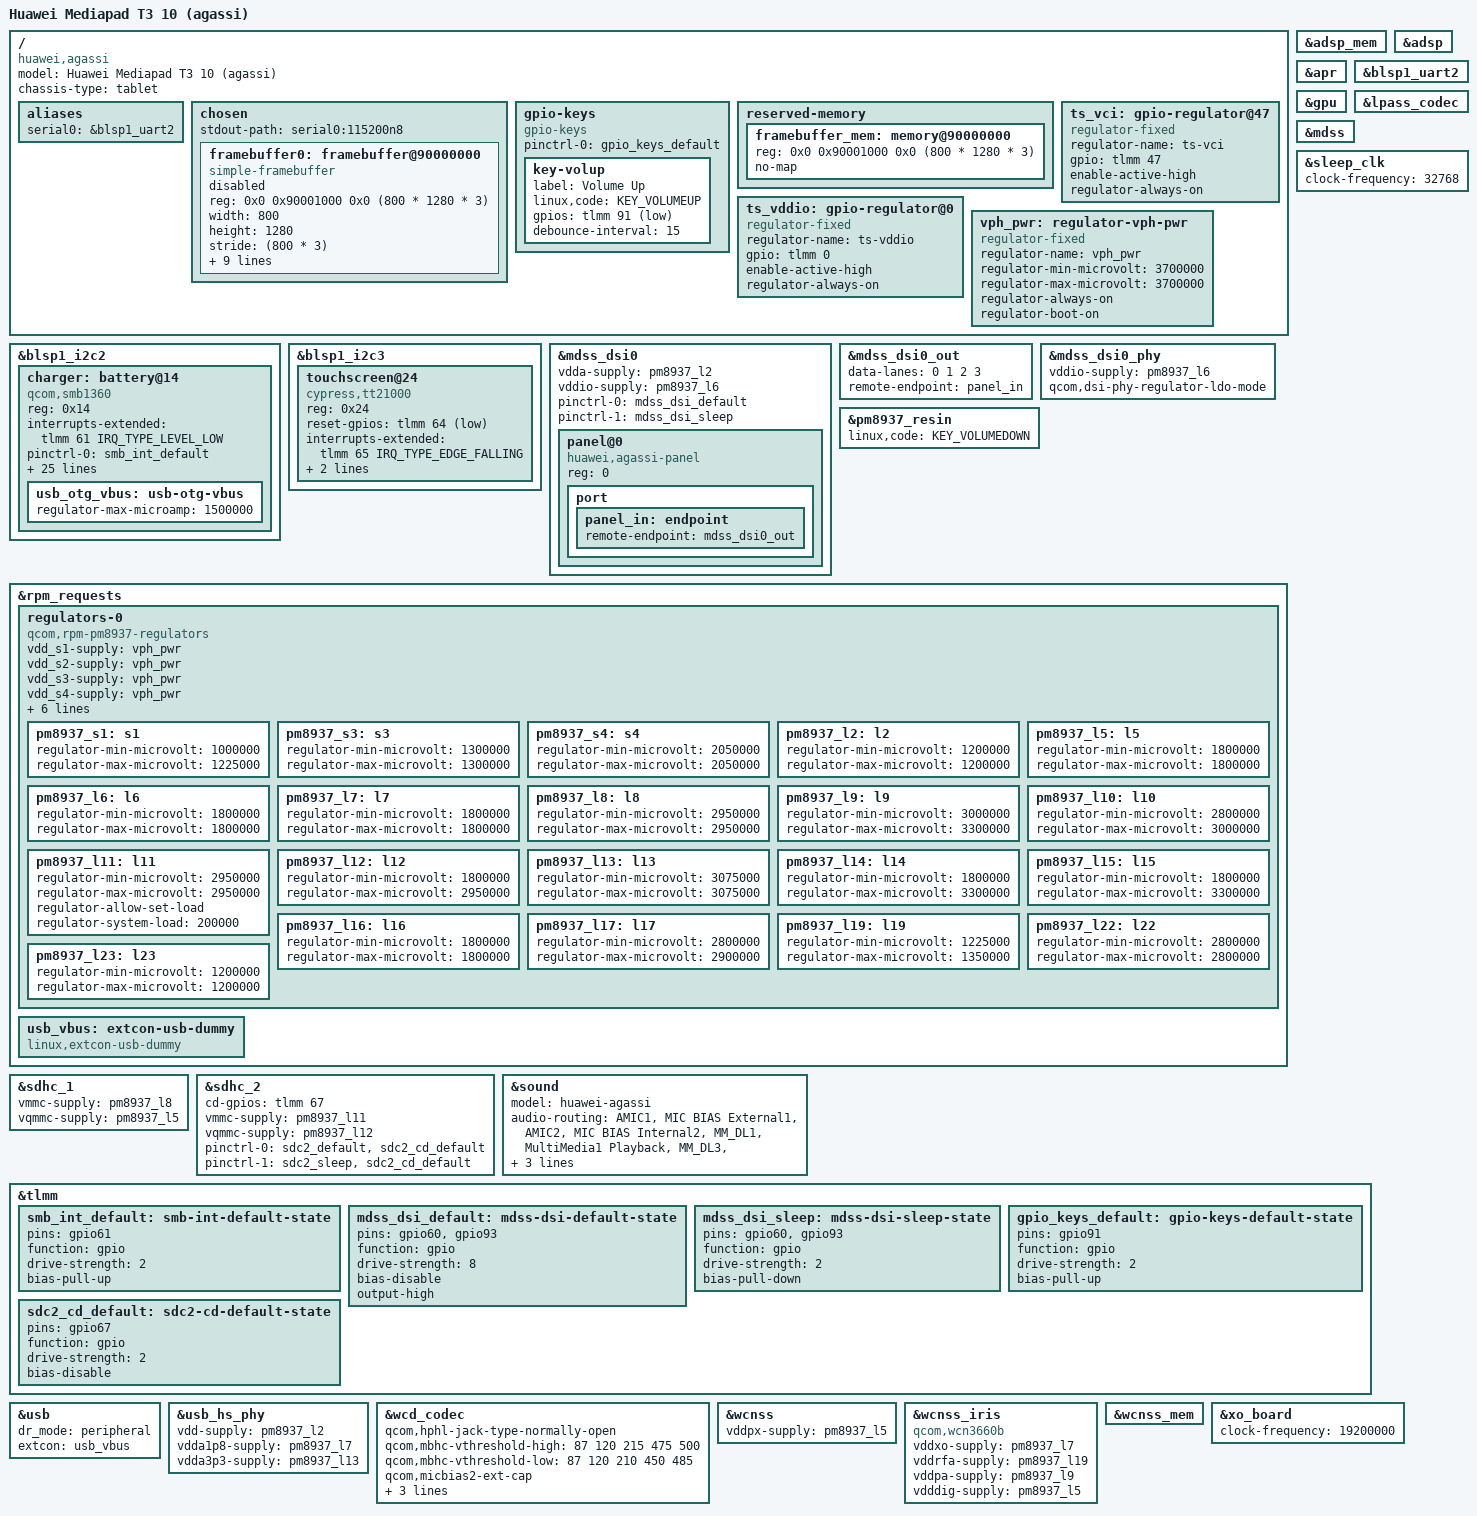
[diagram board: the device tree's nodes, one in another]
// SPDX-License-Identifier: GPL-2.0-only
/*
 * Copyright (c) 2025, Vasiliy Doylov (NekoCWD) <nekodevelopper@gmail.com>
 */

/dts-v1/;

#include <dt-bindings/arm/qcom,ids.h>
#include <dt-bindings/gpio/gpio.h>
#include <dt-bindings/input/linux-event-codes.h>
#include <dt-bindings/leds/common.h>
#include "msm8917.dtsi"
#include "pm8937.dtsi"
#include "msm8937-qdsp6.dtsi"

/ {
	model = "Huawei Mediapad T3 10 (agassi)";
	compatible = "huawei,agassi", "qcom,msm8917";
	chassis-type = "tablet";

	aliases {
		serial0 = &blsp1_uart2;
	};

	chosen {
		stdout-path = "serial0:115200n8";
		#address-cells = <2>;
		#size-cells = <2>;
		ranges;

		framebuffer0: framebuffer@90000000 {
			compatible = "simple-framebuffer";
			reg = <0x0 0x90001000 0x0 (800 * 1280 * 3)>;
			width = <800>;
			height = <1280>;
			stride = <(800 * 3)>;
			format = "r8g8b8";

			clocks = <&gcc GCC_MDSS_AHB_CLK>,
				 <&gcc GCC_MDSS_AXI_CLK>,
				 <&gcc GCC_MDSS_VSYNC_CLK>,
				 <&gcc GCC_MDSS_MDP_CLK>,
				 <&gcc GCC_MDSS_BYTE0_CLK>,
				 <&gcc GCC_MDSS_PCLK0_CLK>,
				 <&gcc GCC_MDSS_ESC0_CLK>;
			power-domains = <&gcc MDSS_GDSC>;
			status = "disabled";
		};
	};

	gpio-keys {
		compatible = "gpio-keys";

		pinctrl-0 = <&gpio_keys_default>;
		pinctrl-names = "default";

		key-volup {
			label = "Volume Up";
			linux,code = <KEY_VOLUMEUP>;
			gpios = <&tlmm 91 GPIO_ACTIVE_LOW>;
			debounce-interval = <15>;
		};
	};

	reserved-memory {
		framebuffer_mem: memory@90000000 {
			reg = <0x0 0x90001000 0x0 (800 * 1280 * 3)>;
			no-map;
		};
	};

	ts_vci: gpio-regulator@47 {
		compatible = "regulator-fixed";
		regulator-name = "ts-vci";
		gpio = <&tlmm 47 GPIO_ACTIVE_HIGH>;
		enable-active-high;
		regulator-always-on;
	};

	ts_vddio: gpio-regulator@0 {
		compatible = "regulator-fixed";
		regulator-name = "ts-vddio";
		gpio = <&tlmm 0 GPIO_ACTIVE_HIGH>;
		enable-active-high;
		regulator-always-on;
	};

	vph_pwr: regulator-vph-pwr {
		compatible = "regulator-fixed";
		regulator-name = "vph_pwr";
		regulator-min-microvolt = <3700000>;
		regulator-max-microvolt = <3700000>;
		regulator-always-on;
		regulator-boot-on;
	};

};

&adsp_mem {
	status = "okay";
};

&adsp {
	status = "okay";
};

&apr {
	status = "okay";
};

&blsp1_i2c2 {
	status = "okay";
	charger: battery@14 {
		compatible = "qcom,smb1360";
		reg = <0x14>;

		interrupts-extended = <&tlmm 61 IRQ_TYPE_LEVEL_LOW>;

		pinctrl-names = "default";
		pinctrl-0 = <&smb_int_default>;

		qcom,chg-inhibit-disabled;
		qcom,iterm-ma = <150>;

		qcom,rsense-10mohm;

		qcom,float-voltage-mv = <4350>;
		qcom,fg-cc-to-cv-mv = <4340>;
		qcom,fg-cutoff-voltage-mv = <3400>;
		qcom,fg-ibatt-standby-ma = <200>;
		qcom,fg-batt-capacity-mah = <4650>;
		qcom,fg-cc-soc-coeff = <0x7B0C>;
		qcom,thermistor-c1-coeff = <0x86C2>;
		qcom,charging-timeout = <768>;
		qcom,recharge-thresh-mv = <100>;
		qcom,fg-auto-recharge-soc = <99>;
		qcom,battery-profile = <0>;

		qcom,fg-iterm-ma = <100>;

		qcom,otp-hard-jeita-config;
		qcom,otp-hot-bat-decidegc = <500>;
		qcom,otp-cold-bat-decidegc = <(-50)>;

		qcom,soft-jeita-config;
		qcom,warm-bat-decidegc = <450>;
		qcom,cool-bat-decidegc = <100>;
		qcom,soft-jeita-comp-voltage-mv = <4000>;
		qcom,soft-jeita-comp-current-ma = <600>;

		qcom,fg-reset-at-pon;
		qcom,fg-reset-threshold-mv = <200>;

		usb_otg_vbus: usb-otg-vbus {
			regulator-max-microamp = <1500000>;
		};
	};
};


&blsp1_i2c3 {
	status = "okay";

	touchscreen@24 {
		compatible = "cypress,tt21000";

		reg = <0x24>;
		reset-gpios = <&tlmm 64 GPIO_ACTIVE_LOW>;
		interrupts-extended = <&tlmm 65 IRQ_TYPE_EDGE_FALLING>;

		vdd-supply = <&ts_vci>;
		vddio-supply = <&ts_vddio>;
	};
};

&blsp1_uart2 {
	status = "okay";
};

&gpu {
	status = "okay";
};

&lpass_codec{
	status = "okay";
};

&mdss {
	status = "okay";
};

&mdss_dsi0 {
	vdda-supply = <&pm8937_l2>;
	vddio-supply = <&pm8937_l6>;

	pinctrl-0 = <&mdss_dsi_default>;
	pinctrl-1 = <&mdss_dsi_sleep>;
	pinctrl-names = "default", "sleep";

	panel@0 {
		compatible = "huawei,agassi-panel";
		reg = <0>;

		port {
			panel_in: endpoint {
				remote-endpoint = <&mdss_dsi0_out>;
			};
		};
	};
};

&mdss_dsi0_out {
	data-lanes = <0 1 2 3>;
	remote-endpoint = <&panel_in>;
};

&mdss_dsi0_phy {
	vddio-supply = <&pm8937_l6>;
	qcom,dsi-phy-regulator-ldo-mode;
};

&pm8937_resin {
	linux,code = <KEY_VOLUMEDOWN>;
	status = "okay";
};

&rpm_requests {
	regulators-0 {
		compatible = "qcom,rpm-pm8937-regulators";

		vdd_s1-supply = <&vph_pwr>;
		vdd_s2-supply = <&vph_pwr>;
		vdd_s3-supply = <&vph_pwr>;
		vdd_s4-supply = <&vph_pwr>;

		vdd_l1_l19-supply = <&pm8937_s3>;
		vdd_l2_l23-supply = <&pm8937_s3>;
		vdd_l3-supply = <&pm8937_s3>;
		vdd_l4_l5_l6_l7_l16-supply = <&pm8937_s4>;
		vdd_l8_l11_l12_l17_l22-supply = <&vph_pwr>;
		vdd_l9_l10_l13_l14_l15_l18-supply = <&vph_pwr>;

		pm8937_s1: s1 {
			regulator-min-microvolt = <1000000>;
			regulator-max-microvolt = <1225000>;
		};

		pm8937_s3: s3 {
			regulator-min-microvolt = <1300000>;
			regulator-max-microvolt = <1300000>;
		};

		pm8937_s4: s4 {
			regulator-min-microvolt = <2050000>;
			regulator-max-microvolt = <2050000>;
		};

		pm8937_l2: l2 {
			regulator-min-microvolt = <1200000>;
			regulator-max-microvolt = <1200000>;
		};

		pm8937_l5: l5 {
			regulator-min-microvolt = <1800000>;
			regulator-max-microvolt = <1800000>;
		};

		pm8937_l6: l6 {
			regulator-min-microvolt = <1800000>;
			regulator-max-microvolt = <1800000>;
		};

		pm8937_l7: l7 {
			regulator-min-microvolt = <1800000>;
			regulator-max-microvolt = <1800000>;
		};

		pm8937_l8: l8 {
			regulator-min-microvolt = <2950000>;
			regulator-max-microvolt = <2950000>;
		};

		pm8937_l9: l9 {
			regulator-min-microvolt = <3000000>;
			regulator-max-microvolt = <3300000>;
		};

		pm8937_l10: l10 {
			regulator-min-microvolt = <2800000>;
			regulator-max-microvolt = <3000000>;
		};

		pm8937_l11: l11 {
			regulator-min-microvolt = <2950000>;
			regulator-max-microvolt = <2950000>;
			regulator-allow-set-load;
			regulator-system-load = <200000>;
		};

		pm8937_l12: l12 {
			regulator-min-microvolt = <1800000>;
			regulator-max-microvolt = <2950000>;
		};

		pm8937_l13: l13 {
			regulator-min-microvolt = <3075000>;
			regulator-max-microvolt = <3075000>;
		};

		pm8937_l14: l14 {
			regulator-min-microvolt = <1800000>;
			regulator-max-microvolt = <3300000>;
		};

		pm8937_l15: l15 {
			regulator-min-microvolt = <1800000>;
			regulator-max-microvolt = <3300000>;
		};

		pm8937_l16: l16 {
			regulator-min-microvolt = <1800000>;
			regulator-max-microvolt = <1800000>;
		};

		pm8937_l17: l17 {
			regulator-min-microvolt = <2800000>;
			regulator-max-microvolt = <2900000>;
		};

		pm8937_l19: l19 {
			regulator-min-microvolt = <1225000>;
			regulator-max-microvolt = <1350000>;
		};

		pm8937_l22: l22 {
			regulator-min-microvolt = <2800000>;
			regulator-max-microvolt = <2800000>;
		};

		pm8937_l23: l23 {
			regulator-min-microvolt = <1200000>;
			regulator-max-microvolt = <1200000>;
		};
	};

	usb_vbus: extcon-usb-dummy {
		compatible = "linux,extcon-usb-dummy";
	};

};

&sdhc_1 {
	vmmc-supply = <&pm8937_l8>;
	vqmmc-supply = <&pm8937_l5>;
	status = "okay";
};

&sdhc_2 {
	cd-gpios = <&tlmm 67 GPIO_ACTIVE_HIGH>;
	vmmc-supply = <&pm8937_l11>;
	vqmmc-supply = <&pm8937_l12>;
	pinctrl-0 = <&sdc2_default &sdc2_cd_default>;
	pinctrl-1 = <&sdc2_sleep &sdc2_cd_default>;
	pinctrl-names = "default", "sleep";

	status = "okay";
};

&sleep_clk {
	clock-frequency = <32768>;
};

&sound {
	model = "huawei-agassi";

	audio-routing =
		"AMIC1", "MIC BIAS External1",
		"AMIC2", "MIC BIAS Internal2",
		"MM_DL1", "MultiMedia1 Playback",
		"MM_DL3", "MultiMedia3 Playback",
		"MM_DL4", "MultiMedia4 Playback",
		"MultiMedia2 Capture", "MM_UL2";

	status = "okay";
};

&tlmm {
	smb_int_default: smb-int-default-state {
		pins = "gpio61";
		function = "gpio";
		drive-strength = <2>;
		bias-pull-up;
	};

	mdss_dsi_default: mdss-dsi-default-state {
		pins = "gpio60", "gpio93";
		function = "gpio";
		drive-strength = <8>;
		bias-disable;
		output-high;
	};

	mdss_dsi_sleep: mdss-dsi-sleep-state {
		pins = "gpio60", "gpio93";
		function = "gpio";
		drive-strength = <2>;
		bias-pull-down;
	};

	gpio_keys_default: gpio-keys-default-state {
		pins = "gpio91";
		function = "gpio";
		drive-strength = <2>;
		bias-pull-up;
	};

	sdc2_cd_default: sdc2-cd-default-state {
		pins = "gpio67";
		function = "gpio";
		drive-strength = <2>;
		bias-disable;
	};
};

&usb {
	dr_mode = "peripheral";
	extcon = <&usb_vbus>;
	status = "okay";
};

&usb_hs_phy {
	vdd-supply = <&pm8937_l2>;
	vdda1p8-supply = <&pm8937_l7>;
	vdda3p3-supply = <&pm8937_l13>;
	status = "okay";
};

&wcd_codec {
	qcom,hphl-jack-type-normally-open;
	qcom,mbhc-vthreshold-high = <87 120 215 475 500>;
	qcom,mbhc-vthreshold-low = <87 120 210 450 485>;
	qcom,micbias2-ext-cap;

	vdd-cdc-io-supply = <&pm8937_l5>;
	vdd-cdc-tx-rx-cx-supply = <&pm8937_s4>;
	vdd-micbias-supply = <&pm8937_l13>;
	status = "okay";
};

&wcnss {
	vddpx-supply = <&pm8937_l5>;
	status = "okay";
};

&wcnss_iris {
	compatible = "qcom,wcn3660b";
	vddxo-supply = <&pm8937_l7>;
	vddrfa-supply = <&pm8937_l19>;
	vddpa-supply = <&pm8937_l9>;
	vdddig-supply = <&pm8937_l5>;
};

&wcnss_mem {
	status = "okay";
};

&xo_board {
	clock-frequency = <19200000>;
};
